# M251_v1 register map
File version: 1.0
Registers are 32-bit, read-write, reset 0x0 unless marked. A register's access mark holds for its fields unless they carry their own. Offsets are from the block's base; [hi:lo] are bit positions; {n}, {i} and the like mark numbered series; 'fields as' and 'values as' point back to an identical list; <NAME> marks a mode.

## CLK — CLK Register Map
Base 0x40000200
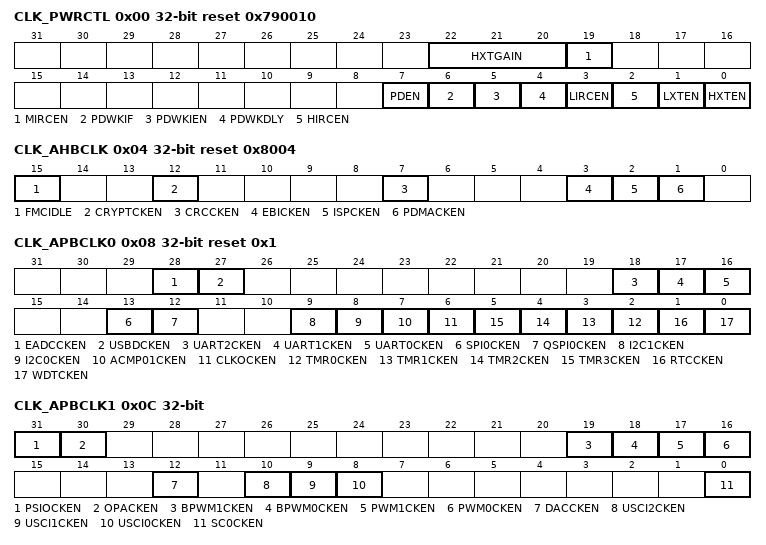
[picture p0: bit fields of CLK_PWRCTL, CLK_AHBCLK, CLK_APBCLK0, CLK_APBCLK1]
0x00 CLK_PWRCTL reset 0x790010 (reset mask 0xFFFF0FF0) — System Power-down Control Register
  [22:20] HXTGAIN — HXT Gain Control Bit (Write Protect). This is a protected register. Please refer to open lock sequence to program it. Gain control is used to enlarge the gain of crystal to make sure crystal work normally. If gain control is enabled, crystal will consume more power than gain control off. Note1: This bit is write protected. Refer to the SYS_REGLCTL register. Note2: Reset by power on reset.
    0=HXT frequency 1~4 MHz; 1=HXT frequency 4~8 MHz; 3=HXT frequency 12~ 16 MHz; 4=HXT frequency 16~24 MHz; 5=HXT frequency 24~32 Mhz
  [19] MIRCEN — MIRC Enable Bit (Write Protect)
    0=4 MHz internal high speed RC oscillator (MIRC) Disabled; 1=4 MHz internal high speed RC oscillator (MIRC) Enabled
  [7] PDEN — System Power-down Enable (Write Protect). When this bit is set to 1, Power-down mode is enabled, chip enters Power-down mode immediately after the PDEN bit set. When chip wakes up from Power-down mode, this bit is auto cleared. Users need to set this bit again for next Power-down. In Power-down mode, HXT ,MIRC and HIRC will be disabled in this mode, but LXT and LIRC are not controlled by Power-down mode. In Power-down mode, the PLL, HCLK, PCLK0 and PCLK1 clocks are disabled, and ignored the clock source selection. The clocks of peripheral are not controlled by Power-down mode, if the peripheral clock source is from LXT or LIRC. Note: This bit is write protected. Refer to the SYS_REGLCTL register.
    0=Chip operating normally or chip in idle mode because of WFI command; 1=Chip enters Power-down mode instant or wait CPU sleep command WFI
  [6] PDWKIF — Power-down Mode Wake-up Interrupt Status. Set by 'Power-down wake-up event' indicates that resume from Power-down mode' The flag is set if any wake-up source is occurred. Refer Power Modes and Wake-up Sources chapter. Note1: Write 1 to clear the bit to 0. Note2: This bit works only if PDWKIEN (CLK_PWRCTL[5]) is set to 1.
  [5] PDWKIEN — Power-down Mode Wake-up Interrupt Enable Bit (Write Protect). Note1: The interrupt will occur when both PDWKIF and PDWKIEN are high. Note2: This bit is write protected. Refer to the SYS_REGLCTL register.
    0=Power-down mode wake-up interrupt Disabled; 1=Power-down mode wake-up interrupt Enabled
  [4] PDWKDLY — Enable the Wake-up Delay Counter (Write Protect). When the chip wakes up from Power-down mode, the clock control will delay certain clock cycles to wait system clock stable. The delayed clock cycle is 4096 clock cycles when chip works at 4~32 MHz external high speed crystal oscillator (HXT), The delayed clock cycle is 512 clock cycles when chip works at 48 MHz internal high speed RC oscillator (HIRC). The delayed clock cycle is 32 clock cycles when chip works at 4 MHz internal median speed RC oscillator (MIRC) . Note: This bit is write protected. Refer to the SYS_REGLCTL register.
    0=Clock cycles delay Disabled; 1=Clock cycles delay Enabled
  [3] LIRCEN — LIRC Enable Bit (Write Protect). Note1: This bit is write protected. Refer to the SYS_REGLCTL register. Note2: LIRC will also be forced on when 1. Power down and ~(CONFIG0[3] & CONFIG0[4] & ~CONFIG0[31] & CONFIG0[30]) 2. Not power down and ~(CONFIG0[3] & CONFIG0[4] & CONFIG0[31])
    0=38.4 kHz internal low speed RC oscillator (LIRC) Disabled; 1=38.4 kHz internal low speed RC oscillator (LIRC) Enabled
  [2] HIRCEN — HIRC Enable Bit (Write Protect). Note: This bit is write protected. Refer to the SYS_REGLCTL register.
    0=48 MHz internal high speed RC oscillator (HIRC) Disabled; 1=48 MHz internal high speed RC oscillator (HIRC) Enabled
  [1] LXTEN — LXT Enable Bit (Write Protect). Note1: This bit is write protected. Refer to the SYS_REGLCTL register. Note2: Reset by RTC powr on reset.
    0=32.768 kHz external low speed crystal (LXT) Disabled; 1=32.768 kHz external low speed crystal (LXT) Enabled
  [0] HXTEN — HXT Enable Bit (Write Protect). Note1: This bit is write protected. Refer to the SYS_REGLCTL register. Note2: Reset by powr on reset.
    0=4~32 MHz external high speed crystal (HXT) Disabled; 1=4~32 MHz external high speed crystal (HXT) Enabled
0x04 CLK_AHBCLK reset 0x8004 — AHB Devices Clock Enable Control Register
  [15] FMCIDLE — Flash Memory Controller Clock Enable Bit in IDLE Mode
    0=FMC clock Disabled when chip is under IDLE mode,in this case, PDMA can not access FMC memory; 1=FMC clock Enabled when chip is under IDLE mode,PDMA can access FMC memory
  [12] CRYPTCKEN — Cryptographic Accelerator Clock Enable Bit
    0=Cryptographic Accelerator clock Disabled; 1=Cryptographic Accelerator clock Enabled
  [7] CRCCKEN — CRC Generator Controller Clock Enable Bit
    0=CRC peripheral clock Disabled; 1=CRC peripheral clock Enabled
  [3] EBICKEN — EBI Controller Clock Enable Bit
    0=EBI peripheral clock Disabled; 1=EBI peripheral clock Enabled
  [2] ISPCKEN — Flash ISP Controller Clock Enable Bit
    0=Flash ISP peripheral clock Disabled; 1=Flash ISP peripheral clock Enabled
  [1] PDMACKEN — PDMA Controller Clock Enable Bit
    0=PDMA peripheral clock Disabled; 1=PDMA peripheral clock Enabled
0x08 CLK_APBCLK0 reset 0x1 — APB Devices Clock Enable Control Register 0
  [28] EADCCKEN — Enhanced Analog-digital-converter (EADC) Clock Enable Bit
    0=EADC clock Disabled; 1=EADC clock Enabled
  [27] USBDCKEN — USB Device Clock Enable Bit
    0=USB Device clock Disabled; 1=USB Device clock Enabled
  [18] UART2CKEN — UART2 Clock Enable Bit
    0=UART2 clock Disabled; 1=UART2 clock Enabled
  [17] UART1CKEN — UART1 Clock Enable Bit
    0=UART1 clock Disabled; 1=UART1 clock Enabled
  [16] UART0CKEN — UART0 Clock Enable Bit
    0=UART0 clock Disabled; 1=UART0 clock Enabled
  [13] SPI0CKEN — SPI0 Clock Enable Bit
    0=SPI0 clock Disabled; 1=SPI0 clock Enabled
  [12] QSPI0CKEN — QSPI0 Clock Enable Bit
    0=QSPI0 clock Disabled; 1=QSPI0 clock Enabled
  [9] I2C1CKEN — I2C1 Clock Enable Bit
    0=I2C1 clock Disabled; 1=I2C1 clock Enabled
  [8] I2C0CKEN — I2C0 Clock Enable Bit
    0=I2C0 clock Disabled; 1=I2C0 clock Enabled
  [7] ACMP01CKEN — Analog Comparator 0/1 Clock Enable Bit
    0=Analog comparator 0/1 clock Disabled; 1=Analog comparator 0/1 clock Enabled
  [6] CLKOCKEN — CLKO Clock Enable Bit
    0=CLKO clock Disabled; 1=CLKO clock Enabled
  [n+2] TMR{n}CKEN (n=0..3) — Timer{n} Clock Enable Bit
    0=Timer{n} clock Disabled; 1=Timer{n} clock Enabled
  [1] RTCCKEN — Real-time-clock APB Interface Clock Enable Bit. This bit is used to control the RTC APB clock only. The RTC peripheral clock source is selected from RTCSEL(CLK_CLKSEL3[8]). It can be selected to 32.768 kHz external low speed crystal or 38.4 kHz internal low speed RC oscillator (LIRC).
    0=RTC clock Disabled; 1=RTC clock Enabled
  [0] WDTCKEN — Watchdog Timer Clock Enable Bit (Write Protect). Note1: This bit is write protected. Refer to the SYS_REGLCTL register. Note2: This bit is forced to 1 when CONFIG0[3] or CONFIG0[4] or CONFIG0[31] is 0. Note3: Reset by power on reset or watch dog reset or software chip reset.
    0=Watchdog timer clock Disabled; 1=Watchdog timer clock Enabled
0x0C CLK_APBCLK1 — APB Devices Clock Enable Control Register 1
  [31] PSIOCKEN — PSIO Clock Enable Bit
    0=PSIO clock Disabled; 1=PSIO clock Enabled
  [30] OPACKEN — OP Amplifier (OPA) Clock Enable Bit
    0=OPA clock Disabled; 1=OPA clock Enabled
  [19] BPWM1CKEN — BPWM1 Clock Enable Bit
    0=BPWM1 clock Disabled; 1=BPWM1 clock Enabled
  [18] BPWM0CKEN — BPWM0 Clock Enable Bit
    0=BPWM0 clock Disabled; 1=BPWM0 clock Enabled
  [17] PWM1CKEN — PWM1 Clock Enable Bit
    0=PWM1 clock Disabled; 1=PWM1 clock Enabled
  [16] PWM0CKEN — PWM0 Clock Enable Bit
    0=PWM0 clock Disabled; 1=PWM0 clock Enabled
  [12] DACCKEN — DAC Clock Enable Bit
    0=DAC clock Disabled; 1=DAC clock Enabled
  [10] USCI2CKEN — USCI2 Clock Enable Bit
    0=USCI1 clock Disabled; 1=USCI1 clock Enabled
  [9] USCI1CKEN — USCI1 Clock Enable Bit
    0=USCI1 clock Disabled; 1=USCI1 clock Enabled
  [8] USCI0CKEN — USCI0 Clock Enable Bit
    0=USCI0 clock Disabled; 1=USCI0 clock Enabled
  [0] SC0CKEN — SC0 Clock Enable Bit
    0=SC0 clock Disabled; 1=SC0 clock Enabled
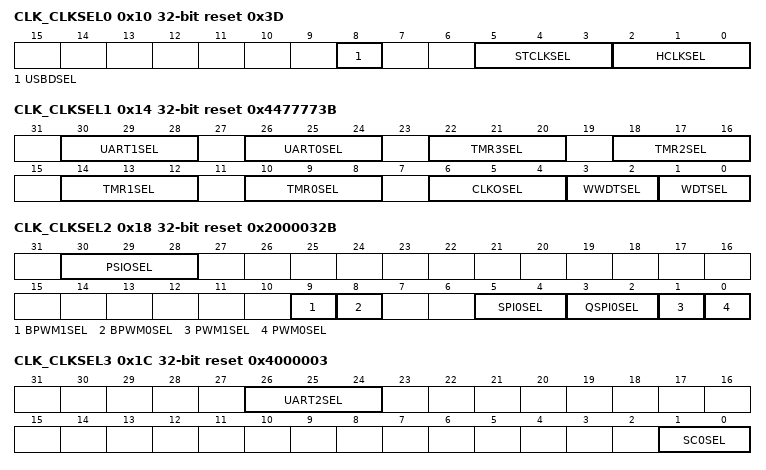
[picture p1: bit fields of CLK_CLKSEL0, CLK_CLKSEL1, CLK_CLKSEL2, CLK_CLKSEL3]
0x10 CLK_CLKSEL0 reset 0x3D — Clock Source Select Control Register 0
  [8] USBDSEL — USB Device Clock Source Selection (Write Protect). These bits are protected bit. It means programming this bit needs to write '59h', '16h', '88h' to address 0x4000_0100 to disable register protection. Refer to the register REGWRPROT at address GCR_BA+0x100.
    0=Clock source from HIRC; 1=Clock source from PLL Divided
  [5:3] STCLKSEL — Cortex-M23 SysTick Clock Source Selection (Write Protect). Note2: This bit is write protected. Refer to the SYS_REGLCTL register.
    0=Clock source from HXT; 1=Clock source from LXT; 2=Clock source from HXT/2; 3=Clock source from HCLK/2; 7=Clock source from HIRC/2
  [2:0] HCLKSEL — HCLK Clock Source Selection (Write Protect). Before clock switching, the related clock sources (both pre-select and new-select) must be turned on. Note1: This bit is write protected. Refer to the SYS_REGLCTL register. Note2: Reset by power on reset.
    0=Clock source from HXT; 1=Clock source from LXT; 2=Clock source from PLL; 3=Clock source from LIRC; 5=Clock source from MIRC; 7=Clock source from HIRC
0x14 CLK_CLKSEL1 reset 0x4477773B — Clock Source Select Control Register 1
  [30:28] UART1SEL — UART1 Clock Source Selection
    0=Clock source from 4~32 MHz external high speed crystal oscillator (HXT); 1=Clock source from PLL; 2=Clock source from 32.768 kHz external low speed crystal oscillator (LXT); 3=Clock source from 48 MHz internal high speed RC oscillator (HIRC); 4=Clock source from PCLK1; 5=Clock source from 38.4 kHz internal low speed RC oscillator (LIRC)
  [26:24] UART0SEL — UART0 Clock Source Selection
    0=Clock source from 4~32 MHz external high speed crystal oscillator (HXT); 1=Clock source from PLL; 2=Clock source from 32.768 kHz external low speed crystal oscillator (LXT); 3=Clock source from 48 MHz internal high speed RC oscillator (HIRC); 4=Clock source from PCLK0; 5=Clock source from 38.4 kHz internal low speed RC oscillator (LIRC)
  [22:20] TMR3SEL — TIMER3 Clock Source Selection
    0=Clock source from 4~32 MHz external high speed crystal oscillator (HXT); 1=Clock source from 32.768 kHz external low speed crystal oscillator (LXT); 2=Clock source from PCLK1; 3=Clock source from external clock T3 pin; 5=Clock source from 38.4 kHz internal low speed RC oscillator (LIRC); 7=Clock source from 48 MHz internal high speed RC oscillator (HIRC)
  [18:16] TMR2SEL — TIMER2 Clock Source Selection
    0=Clock source from 4~32 MHz external high speed crystal oscillator (HXT); 1=Clock source from 32.768 kHz external low speed crystal oscillator (LXT); 2=Clock source from PCLK1; 3=Clock source from external clock T2 pin; 5=Clock source from 38.4 kHz internal low speed RC oscillator (LIRC); 7=Clock source from 48 MHz internal high speed RC oscillator (HIRC)
  [14:12] TMR1SEL — TIMER1 Clock Source Selection
    0=Clock source from 4~32 MHz external high speed crystal oscillator (HXT); 1=Clock source from 32.768 kHz external low speed crystal oscillator (LXT); 2=Clock source from PCLK0; 3=Clock source from external clock T1 pin; 5=Clock source from 38.4 kHz internal low speed RC oscillator (LIRC); 7=Clock source from 48 MHz internal high speed RC oscillator (HIRC)
  [10:8] TMR0SEL — TIMER0 Clock Source Selection
    0=Clock source from 4~32 MHz external high speed crystal oscillator (HXT); 1=Clock source from 32.768 kHz external low speed crystal oscillator (LXT); 2=Clock source from PCLK0; 3=Clock source from external clock T0 pin; 5=Clock source from 38.4 kHz internal low speed RC oscillator (LIRC); 7=Clock source from 48 MHz internal high speed RC oscillator (HIRC)
  [6:4] CLKOSEL — Clock Divider Clock Source Selection
    0=Clock source from 4~32 MHz external high speed crystal oscillator (HXT); 1=Clock source from 32.768 kHz external low speed crystal oscillator (LXT); 2=Clock source from HCLK; 3=Clock source from 48 MHz internal high speed RC oscillator (HIRC); 4=Clock source from 38.4 kHz internal low speed RC oscillator (LIRC); 5=Clock source from 4 MHz internal medium speed RC oscillator (MIRC); 6=Clock source from PLL; 7=Clock source from USB SOF
  [3:2] WWDTSEL — Window Watchdog Timer Clock Source Selection (Write Protect)
    2=Clock source from HCLK/2048; 3=Clock source from 38.4 kHz internal low speed RC oscillator (LIRC)
  [1:0] WDTSEL — Watchdog Timer Clock Source Selection (Write Protect). Note1: This bit is write protected. Refer to the SYS_REGLCTL register. Note2: This bit is forced to 11 when CONFIG0[31] or CONFIG0[4] or CONFIG0[3] is 0.
    1=Clock source from 32.768 kHz external low speed crystal oscillator (LXT); 2=Clock source from HCLK/2048; 3=Clock source from 38.4 kHz internal low speed RC oscillator (LIRC)
0x18 CLK_CLKSEL2 reset 0x2000032B — Clock Source Select Control Register 2
  [30:28] PSIOSEL — PSIO Clock Source Selection
    0=Clock source from 4~32 MHz external high speed crystal oscillator (HXT); 1=Clock source from 32.768 kHz external low speed crystal oscillator (LXT); 2=Clock source from PCLK1; 3=Clock source from PLL; 4=Clock source from 38.4 kHz internal low speed RC oscillator (LIRC); 7=Clock source from 48 MHz internal high speed RC oscillator (HIRC)
  [9] BPWM1SEL — BPWM1 Clock Source Selection. The peripheral clock source of BPWM1 is defined by BPWM1SEL.
    0=Clock source from PLL; 1=Clock source from PCLK1
  [8] BPWM0SEL — BPWM0 Clock Source Selection. The peripheral clock source of BPWM0 is defined by BPWM0SEL.
    0=Clock source from PLL; 1=Clock source from PCLK0
  [5:4] SPI0SEL — SPI0 Clock Source Selection
    0=Clock source from 4~32 MHz external high speed crystal oscillator (HXT); 1=Clock source from PLL; 2=Clock source from PCLK1; 3=Clock source from 48 MHz internal high speed RC oscillator (HIRC)
  [3:2] QSPI0SEL — QSPI0 Clock Source Selection
    0=Clock source from 4~32 MHz external high speed crystal oscillator (HXT); 1=Clock source from PLL; 2=Clock source from PCLK0; 3=Clock source from 48 MHz internal high speed RC oscillator (HIRC)
  [1] PWM1SEL — PWM1 Clock Source Selection. The peripheral clock source of PWM1 is defined by PWM1SEL.
    0=Clock source from PLL; 1=Clock source from PCLK1
  [0] PWM0SEL — PWM0 Clock Source Selection. The peripheral clock source of PWM0 is defined by PWM0SEL.
    0=Clock source from PLL; 1=Clock source from PCLK0
0x1C CLK_CLKSEL3 reset 0x4000003 — Clock Source Select Control Register 3
  [26:24] UART2SEL — UART2 Clock Source Selection
    values as CLK_CLKSEL1.UART0SEL
  [1:0] SC0SEL — SC0 Clock Source Selection
    values as CLK_CLKSEL2.QSPI0SEL
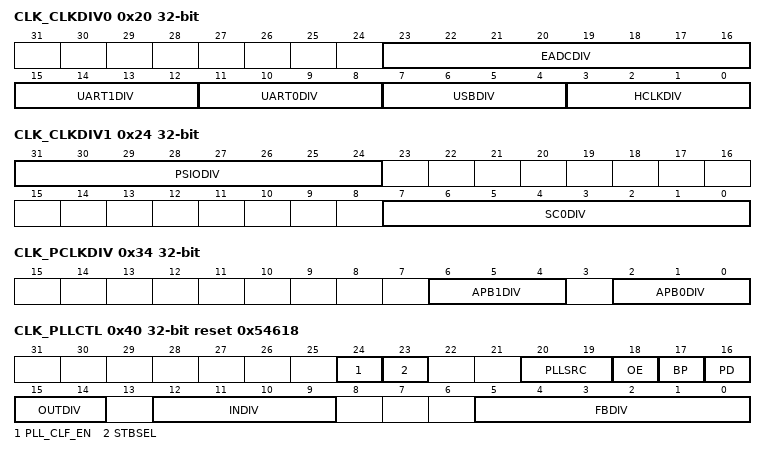
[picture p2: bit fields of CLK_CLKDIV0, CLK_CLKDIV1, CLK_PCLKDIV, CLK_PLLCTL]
0x20 CLK_CLKDIV0 — Clock Divider Number Register 0
  [23:16] EADCDIV — EADC Clock Divide Number From EADC Clock Source
  [15:12] UART1DIV — UART1 Clock Divide Number From UART1 Clock Source
  [11:8] UART0DIV — UART0 Clock Divide Number From UART0 Clock Source
  [7:4] USBDIV — USB Clock Divide Number From PLL Clock
  [3:0] HCLKDIV — HCLK Clock Divide Number From HCLK Clock Source
0x24 CLK_CLKDIV1 — Clock Divider Number Register 1
  [31:24] PSIODIV — PSIO Clock Divide Number From PSIO Clock Source
  [7:0] SC0DIV — SC0 Clock Divide Number From SC0 Clock Source
0x30 CLK_CLKDIV4 — Clock Divider Number Register 4
  [3:0] UART2DIV — UART2 Clock Divide Number From UART2 Clock Source
0x34 CLK_PCLKDIV — APB Clock Divider Register
  [6:4] APB1DIV — APB1 Clock DIvider. APB1 clock can be divided from HCLK. Others: Reserved.
  [2:0] APB0DIV — APB0 Clock DIvider. APB0 clock can be divided from HCLK. Others: Reserved.
0x40 CLK_PLLCTL reset 0x54618 — PLL Control Register
  [24] PLL_CLF_EN — 1: PLL Clock Filter On. 0 : OFF
  [23] STBSEL — PLL Stable Counter Selection (Write Protect). Note: This bit is write protected. Refer to the SYS_REGLCTL register.
    0=PLL stable time is 1200 PLL source clock (suitable for source clock is equal to or less than 12 MHz); 1=PLL stable time is 3200 PLL source clock (suitable for source clock is larger than 12 MHz)
  [20:19] PLLSRC — PLL Source Clock Selection (Write Protect). Note: This bit is write protected. Refer to the SYS_REGLCTL register. Note: MIRC and HIRC have to be both on when source switch between them
    0=PLL source clock from 4~32 MHz external high-speed crystal oscillator (HXT); 1=PLL source clock from 12 MHz internal high-speed oscillator (HIRC/4); 2=PLL source clock from 4~32 MHz external high-speed crystal oscillator (HXT); 3=PLL source clock from 4 MHz internal high-speed oscillator (MIRC)
  [18] OE — PLL OE (FOUT Enable) Pin Control (Write Protect). Note: This bit is write protected. Refer to the SYS_REGLCTL register.
    0=PLL FOUT Enabled; 1=PLL FOUT is fixed low
  [17] BP — PLL Bypass Control (Write Protect). Note: This bit is write protected. Refer to the SYS_REGLCTL register.
    0=PLL is in normal mode (default); 1=PLL clock output is same as PLL input clock FIN
  [16] PD — Power-down Mode (Write Protect). If set the PDEN bit to 1 in CLK_PWRCTL register, the PLL will enter Power-down mode, too. Note: This bit is write protected. Refer to the SYS_REGLCTL register.
    0=PLL is in normal mode; 1=PLL is in Power-down mode (default)
  [15:14] OUTDIV — PLL Output Divider Control (Write Protect). Refer to the formulas below the table. Note: This bit is write protected. Refer to the SYS_REGLCTL register.
  [12:9] INDIV — PLL Input Divider Control (Write Protect). Refer to the formulas below the table. Note: This bit is write protected. Refer to the SYS_REGLCTL register.
  [5:0] FBDIV — PLL Feedback Divider Control (Write Protect). Refer to the formulas below the table. Note: This bit is write protected. Refer to the SYS_REGLCTL register.
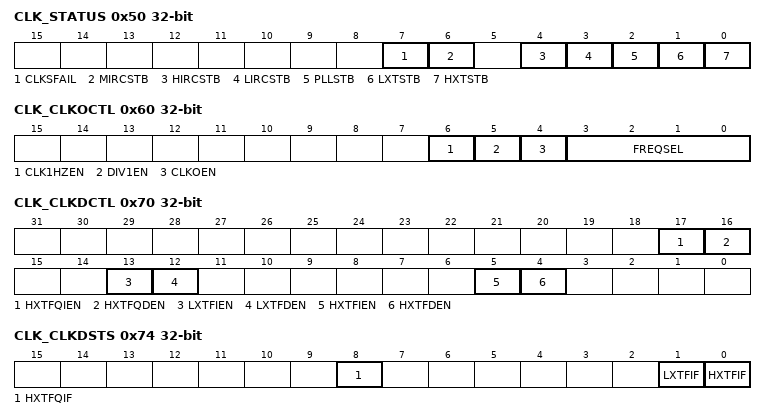
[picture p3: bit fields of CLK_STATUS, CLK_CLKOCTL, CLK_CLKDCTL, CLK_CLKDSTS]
0x50 CLK_STATUS ro (reset mask 0xFFFFFF00) — Clock Status Monitor Register
  [7] CLKSFAIL — Clock Switching Fail Flag. This bit is updated when software switches system clock source. If switch target clock is stable, this bit will be set to 0. If switch target clock is not stable, this bit will be set to 1. Note: Write 1 to clear the bit to 0.
    0=Clock switching success; 1=Clock switching failure
  [6] MIRCSTB — MIRC Clock Source Stable Flag (Read Only)
    0=4 MHz internal mid speed RC oscillator (MIRC) clock is not stable or disabled; 1=4 MHz internal mid speed RC oscillator (MIRC) clock is stable and enabled
  [4] HIRCSTB — HIRC Clock Source Stable Flag (Read Only)
    0=48 MHz internal high speed RC oscillator (HIRC) clock is not stable or disabled; 1=48 MHz internal high speed RC oscillator (HIRC) clock is stable and enabled
  [3] LIRCSTB — LIRC Clock Source Stable Flag (Read Only)
    0=38.4 kHz internal low speed RC oscillator (LIRC) clock is not stable or disabled; 1=38.4 kHz internal low speed RC oscillator (LIRC) clock is stable and enabled
  [2] PLLSTB — Internal PLL Clock Source Stable Flag (Read Only)
    0=Internal PLL clock is not stable or disabled; 1=Internal PLL clock is stable and enabled
  [1] LXTSTB — LXT Clock Source Stable Flag (Read Only)
    0=32.768 kHz external low speed crystal oscillator (LXT) clock is not stable or disabled; 1=32.768 kHz external low speed crystal oscillator (LXT) clock is stabled and enabled
  [0] HXTSTB — HXT Clock Source Stable Flag (Read Only)
    0=4~32 MHz external high speed crystal oscillator (HXT) clock is not stable or disabled; 1=4~32 MHz external high speed crystal oscillator (HXT) clock is stable and enabled
0x60 CLK_CLKOCTL — Clock Output Control Register
  [6] CLK1HZEN — Clock Output 1Hz Enable Bit
    0=1 Hz clock output for 32.768 kHz frequency compensation Disabled; 1=1 Hz clock output for 32.768 kHz frequency compensation Enabled
  [5] DIV1EN — Clock Output Divide One Enable Bit
    0=Clock Output will output clock with source frequency divided by FREQSEL; 1=Clock Output will output clock with source frequency
  [4] CLKOEN — Clock Output Enable Bit
    0=Clock Output function Disabled; 1=Clock Output function Enabled
  [3:0] FREQSEL — Clock Output Frequency Selection. The formula of output frequency is. Fin is the input clock frequency. Fout is the frequency of divider output clock. N is the 4-bit value of FREQSEL[3:0].
0x70 CLK_CLKDCTL — Clock Fail Detector Control Register
  [17] HXTFQIEN — HXT Clock Frequency Range Detector Interrupt Enable Bit
    0=4~32 MHz external high speed crystal oscillator (HXT) clock frequency range detector fail interrupt Disabled; 1=4~32 MHz external high speed crystal oscillator (HXT) clock frequency range detector fail interrupt Enabled
  [16] HXTFQDEN — HXT Clock Frequency Range Detector Enable Bit
    0=4~32 MHz external high speed crystal oscillator (HXT) clock frequency range detector Disabled; 1=4~32 MHz external high speed crystal oscillator (HXT) clock frequency range detector Enabled
  [13] LXTFIEN — LXT Clock Fail Interrupt Enable Bit
    0=32.768 kHz external low speed crystal oscillator (LXT) clock fail interrupt Disabled; 1=32.768 kHz external low speed crystal oscillator (LXT) clock fail interrupt Enabled
  [12] LXTFDEN — LXT Clock Fail Detector Enable Bit
    0=32.768 kHz external low speed crystal oscillator (LXT) clock fail detector Disabled; 1=32.768 kHz external low speed crystal oscillator (LXT) clock fail detector Enabled
  [5] HXTFIEN — HXT Clock Fail Interrupt Enable Bit
    0=4~32 MHz external high speed crystal oscillator (HXT) clock fail interrupt Disabled; 1=4~32 MHz external high speed crystal oscillator (HXT) clock fail interrupt Enabled
  [4] HXTFDEN — HXT Clock Fail Detector Enable Bit
    0=4~32 MHz external high speed crystal oscillator (HXT) clock fail detector Disabled; 1=4~32 MHz external high speed crystal oscillator (HXT) clock fail detector Enabled
0x74 CLK_CLKDSTS — Clock Fail Detector Status Register
  [8] HXTFQIF — HXT Clock Frequency Range Detector Interrupt Flag (Write Protect). Note: Write 1 to clear the bit to 0.
    0=4~32 MHz external high speed crystal oscillator (HXT) clock frequency is normal; 1=4~32 MHz external high speed crystal oscillator (HXT) clock frequency is abnormal
  [1] LXTFIF — LXT Clock Fail Interrupt Flag (Write Protect). Note: Write 1 to clear the bit to 0.
    0=32.768 kHz external low speed crystal oscillator (LXT) clock is normal; 1=32.768 kHz external low speed crystal oscillator (LXT) stops
  [0] HXTFIF — HXT Clock Fail Interrupt Flag (Write Protect). Note: Write 1 to clear the bit to 0.
    0=4~32 MHz external high speed crystal oscillator (HXT) clock is normal; 1=4~32 MHz external high speed crystal oscillator (HXT) clock stops
0x78 CLK_CDUPB — Clock Frequency Range Detector Upper Boundary Register
  [9:0] UPERBD — HXT Clock Frequency Range Detector Upper Boundary Value. The bits define the maximum value of frequency range detector window. When HXT frequency higher than this maximum frequency value, the HXT Clock Frequency Range Detector Interrupt Flag will set to 1. Note :Frequency out of range will be asserted when HIRC_period*1024> HXT_period*CLK_DUPB or HIRC_period*1024 < HXT_period*CLK_CDLOWB.
0x7C CLK_CDLOWB — Clock Frequency Range Detector Lower Boundary Register
  [9:0] LOWERBD — HXT Clock Frequency Range Detector Lower Boundary Value. The bits define the minimum value of frequency range detector window. When HXT frequency lower than this minimum frequency value, the HXT Clock Frequency Range Detector Interrupt Flag will set to 1. Note :The frequency out of range will be asserted when HIRC_period*1024> HXT_period*CLK_DUPB or HIRC_period*1024 < HXT_period*CLK_CDLOWB.
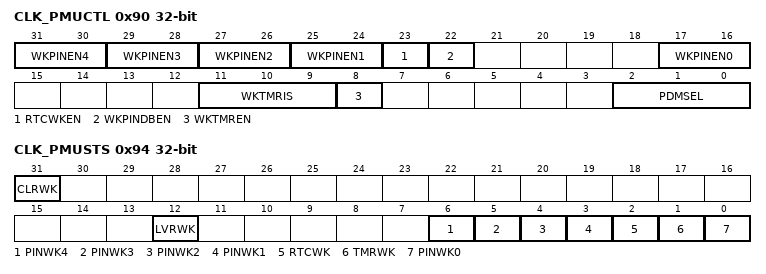
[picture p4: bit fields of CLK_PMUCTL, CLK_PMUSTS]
0x90 CLK_PMUCTL — Power Manager Control Register
  [31:30] WKPINEN4 — Wake-up Pin Enable 4 (Write Protect). This is a protected register. Please refer to open lock sequence to program it. This is control register for PF.6 to wake-up pin. Note: This bit is write protected. Refer to the SYS_REGLCTL register.
    0=Wake-up pin disable at Deep Power-down mode; 1=Wake-up pin rising edge enabled at Deep Power-down mode; 2=Wake-up pin falling edge enabled at Deep Power-down mode; 3=Wake-up pin both edge enabled at Deep Power-down mode
  [29:28] WKPINEN3 — Wake-up Pin Enable 3 (Write Protect). This is a protected register. Please refer to open lock sequence to program it. This is control register for PB.12 to wake-up pin. Note: This bit is write protected. Refer to the SYS_REGLCTL register.
    values as WKPINEN4
  [27:26] WKPINEN2 — Wake-up Pin Enable 2 (Write Protect). This is a protected register. Please refer to open lock sequence to program it. This is control register for PB.2 to wake-up pin. Note: This bit is write protected. Refer to the SYS_REGLCTL register.
    values as WKPINEN4
  [25:24] WKPINEN1 — Wake-up Pin Enable 1 (Write Protect). This is a protected register. Please refer to open lock sequence to program it. This is control register for PB.0 to wake-up pin. Note: This bit is write protected. Refer to the SYS_REGLCTL register.
    values as WKPINEN4
  [23] RTCWKEN — RTC Wake-up Enable (Write Protect). This is a protected register. Please refer to open lock sequence to program it. Note: This bit is write protected. Refer to the SYS_REGLCTL register.
    0=RTC wake-up disable at Deep Power-down mode or Standby Power-down mode; 1=RTC wake-up enabled at Deep Power-down mode or Standby Power-down mode
  [22] WKPINDBEN — Wake-up Pin De-bounce Enable Bit (Write Protect). The WKPINDBEN bit is used to enable the de-bounce function for wake-up pin. If the input signal pulse width cannot be sampled by continuous eight de-bounce sample cycle, the input signal transition is seen as the signal bounce and will not trigger the wakeup. The de-bounce clock source is the 38 kHz internal low speed RC oscillator (LIRC). The de-bounce function is valid only for edge triggered.
    0=Deep power-down wake-up pin De-bounce function disable; 1=Deep power-down wake-up pin De-bounce function enable
  [17:16] WKPINEN0 — Wake-up Pin Enable 0 (Write Protect). This is a protected register. Please refer to open lock sequence to program it. This is control register for PC.0 to wake-up pin. Note: This bit is write protected. Refer to the SYS_REGLCTL register.
    values as WKPINEN4
  [11:9] WKTMRIS — Wake-up Timer Time-out Interval Select (Write Protect). This is a protected register. Please refer to open lock sequence to program it. These bits control wake-up timer time-out interval when chip at DPD mode. Note: This bit is write protected. Refer to the SYS_REGLCTL register.
    0=Time-out interval is 128 LIRC clocks (~3.368 ms); 1=Time-out interval is 256 LIRC clocks (~6.736 ms); 2=Time-out interval is 512 LIRC clocks (~13.47 ms); 3=Time-out interval is 1024 LIRC clocks (~26.95 ms); 4=Time-out interval is 4096 LIRC clocks (~107.79 ms); 5=Time-out interval is 8192 LIRC clocks (~215.58 ms); 6=Time-out interval is 16384 LIRC clocks (~431.16 ms); 7=Time-out interval is 32768 LIRC clocks (~862.32 ms)
  [8] WKTMREN — Wake-up Timer Enable (Write Protect). This is a protected register. Please refer to open lock sequence to program it. Note: This bit is write protected. Refer to the SYS_REGLCTL register
    0=Wake-up timer disable at DPD mode; 1=Wake-up timer enabled at DPD mode
  [2:0] PDMSEL — Power-down Mode Selection (Write Protect). This is a protected register. Please refer to open lock sequence to program it. These bits control chip power-down mode grade selection when CPU execute WFI/WFE instruction. Note: This bit is write protected. Refer to the SYS_REGLCTL register.
    0=Power-down mode is selected. (PD); 2=fast wake up; 6=Deep Power-down mode is selected (DPD)
0x94 CLK_PMUSTS — Power Manager Status Register
  [31] CLRWK — Clear Wake-up Flag. Note: Reset by powr on reset.
    0=Not cleared; 1=Clear all wake-up flag
  [12] LVRWK ro — LVR Wake-up Flag (Read Only). This flag indicates that wakeup of device from Deep Power-down mode was requested with a LVR happened. This flag is cleared when DPD mode is entered.
  [6] PINWK4 ro — Pin Wake-up 4 Flag (Read Only). This flag indicates that wake-up of chip from Deep Power-down mode was requested by a transition of the WAKEUP pin (GPF.6). This flag is cleared when DPD mode is entered.
  [5] PINWK3 ro — Pin Wake-up 3 Flag (Read Only). This flag indicates that wake-up of chip from Deep Power-down mode was requested by a transition of the WAKEUP pin (GPB.12). This flag is cleared when DPD mode is entered.
  [4] PINWK2 ro — Pin Wake-up 2 Flag (Read Only). This flag indicates that wake-up of chip from Deep Power-down mode was requested by a transition of the WAKEUP pin (GPB.2). This flag is cleared when DPD mode is entered.
  [3] PINWK1 ro — Pin Wake-up 1 Flag (Read Only). This flag indicates that wake-up of chip from Deep Power-down mode was requested by a transition of the WAKEUP pin (GPB.0). This flag is cleared when DPD mode is entered.
  [2] RTCWK ro — RTC Wake-up Flag (Read Only). This flag indicates that wakeup of device from Deep Power-down mode (DPD) was requested with a RTC alarm, tick time or tamper happened. This flag is cleared when DPD mode is entered.
  [1] TMRWK ro — Timer Wake-up Flag (Read Only). This flag indicates that wake-up of chip from Deep Power-down mode (DPD) was requested by wakeup timer time-out. This flag is cleared when DPD mode is entered.
  [0] PINWK0 ro — Pin Wake-up 0 Flag (Read Only). This flag indicates that wake-up of chip from Deep Power-down mode was requested by a transition of the WAKEUP pin (GPC.0). This flag is cleared when DPD mode is entered.
0xB4 CLK_HXTFSEL (reset mask 0xFFFFFFF0) — HXT Filter Select Control Register
  [0] HXTFSEL — HXT Filter Select. Note1: This bit is write protected. Refer to the SYS_REGLCTL register. Note2: This bit should not be changed during HXT running.
    0=HXT frequency is greater than 12 MHz; 1=HXT frequency is less than or equal to 12 MHz
